VERSION "smart-cockpit 1.0"

NS_ :

BS_:

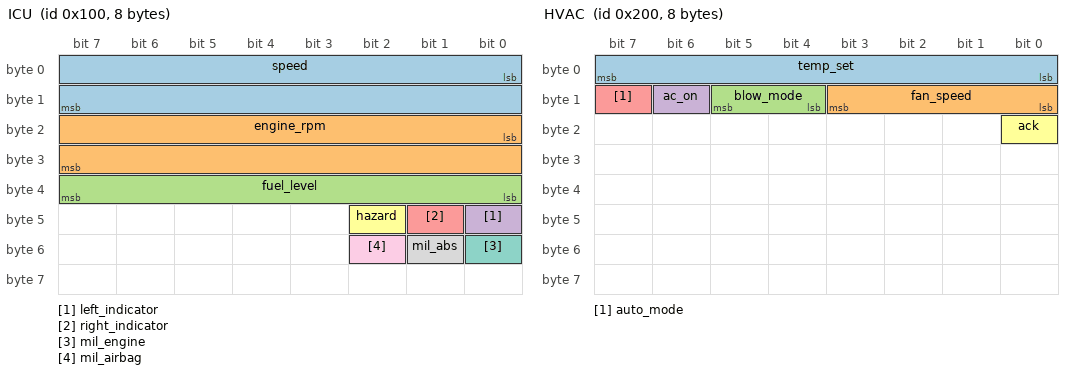
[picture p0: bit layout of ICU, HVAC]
BO_ 256 ICU: 8 ICU
 SG_ speed : 0|16@1+ (1,0) [0|240] "km/h" ICU
 SG_ engine_rpm : 16|16@1+ (1,0) [0|8000] "rpm" ICU
 SG_ fuel_level : 32|8@1+ (0.5,0) [0|100] "%" ICU
 SG_ left_indicator : 40|1@1+ (1,0) [0|1] "" ICU
 SG_ right_indicator : 41|1@1+ (1,0) [0|1] "" ICU
 SG_ hazard : 42|1@1+ (1,0) [0|1] "" ICU
 SG_ mil_engine : 48|1@1+ (1,0) [0|1] "" ICU
 SG_ mil_abs : 49|1@1+ (1,0) [0|1] "" ICU
 SG_ mil_airbag : 50|1@1+ (1,0) [0|1] "" ICU

BO_ 512 HVAC: 8 HVAC
 SG_ temp_set : 0|8@1+ (1,0) [16|30] "C" HVAC
 SG_ fan_speed : 8|4@1+ (1,0) [0|7] "" HVAC
 SG_ blow_mode : 12|2@1+ (1,0) [0|3] "" HVAC
 SG_ ac_on : 14|1@1+ (1,0) [0|1] "" HVAC
 SG_ auto_mode : 15|1@1+ (1,0) [0|1] "" HVAC
 SG_ ack : 16|1@1+ (1,0) [0|1] "" HVAC

BO_ 768 Gear: 8 Gear
 SG_ gear_signal : 0|8@1+ (1,0) [0|7] "" Gear

BO_ 1024 Chassis: 8 Chassis
 SG_ steering_angle : 0|16@1- (0.1,0) [-900|900] "deg" Chassis
